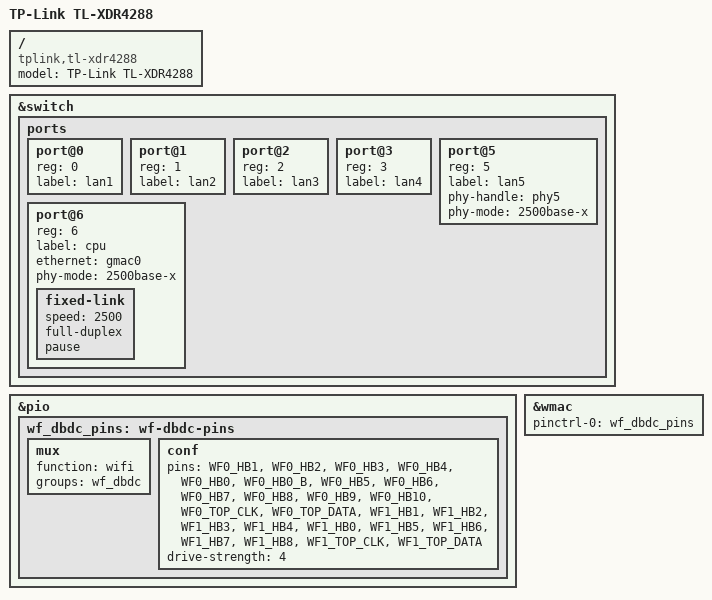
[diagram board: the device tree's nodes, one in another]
// SPDX-License-Identifier: GPL-2.0-or-later OR MIT

/dts-v1/;
#include "mt7986a-tl-xdr-common.dtsi"

/ {
	model = "TP-Link TL-XDR4288";
	compatible = "tplink,tl-xdr4288", "mediatek,mt7986a";
};

&switch {
	ports {
		#address-cells = <1>;
		#size-cells = <0>;

		port@0 {
			reg = <0>;
			label = "lan1";
		};

		port@1 {
			reg = <1>;
			label = "lan2";
		};

		port@2 {
			reg = <2>;
			label = "lan3";
		};

		port@3 {
			reg = <3>;
			label = "lan4";
		};

		port@5 {
			reg = <5>;
			label = "lan5";
			phy-handle = <&phy5>;
			phy-mode = "2500base-x";
		};

		port@6 {
			reg = <6>;
			label = "cpu";
			ethernet = <&gmac0>;
			phy-mode = "2500base-x";

			fixed-link {
				speed = <2500>;
				full-duplex;
				pause;
			};
		};
	};
};

&pio {
	wf_dbdc_pins: wf-dbdc-pins {
		mux {
			function = "wifi";
			groups = "wf_dbdc";
		};
		conf {
			pins = "WF0_HB1", "WF0_HB2", "WF0_HB3", "WF0_HB4",
			       "WF0_HB0", "WF0_HB0_B", "WF0_HB5", "WF0_HB6",
			       "WF0_HB7", "WF0_HB8", "WF0_HB9", "WF0_HB10",
			       "WF0_TOP_CLK", "WF0_TOP_DATA", "WF1_HB1",
			       "WF1_HB2", "WF1_HB3", "WF1_HB4", "WF1_HB0",
			       "WF1_HB5", "WF1_HB6", "WF1_HB7", "WF1_HB8",
			       "WF1_TOP_CLK", "WF1_TOP_DATA";
			drive-strength = <4>;
		};
	};
};

&wmac {
	pinctrl-names = "dbdc";
	pinctrl-0 = <&wf_dbdc_pins>;
};
